# MCU_CPSW0_ECC register map
Vendor: Texas Instruments
Peripheral module from a debugger description file (folder am65x).
Registers are 32-bit, access not given, reset 0x0 unless marked. A register's access mark holds for its fields unless they carry their own. Offsets are as the file gives them; lines under a group give offsets from that group; [hi:lo] are bit positions; {n}, {i} and the like mark numbered series; 'fields as' and 'values as' point back to an identical list; <NAME> marks a mode.

## MCU_CPSW0_ECC
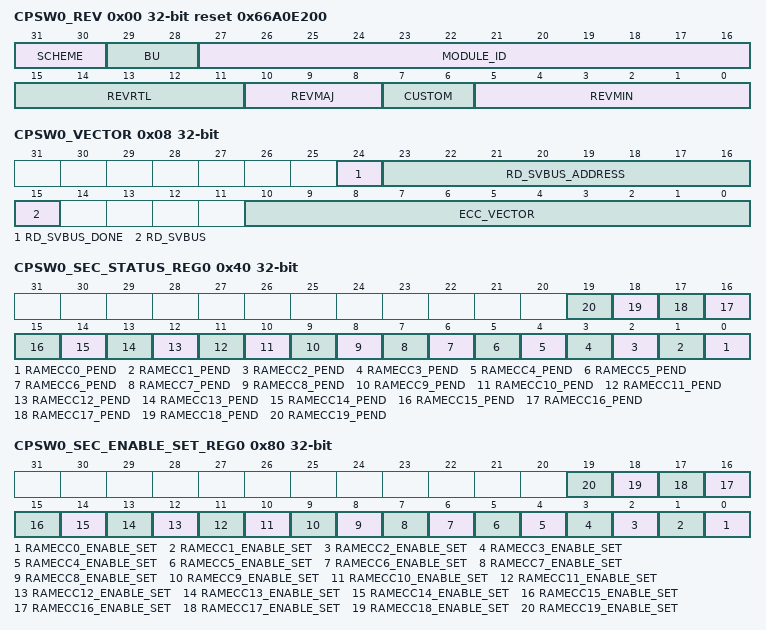
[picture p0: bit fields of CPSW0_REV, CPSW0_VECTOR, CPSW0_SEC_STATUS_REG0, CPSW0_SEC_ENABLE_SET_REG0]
0x00 CPSW0_REV ro reset 0x66A0E200 — Revision parameters
  [31:30] SCHEME
  [29:28] BU
  [27:16] MODULE_ID
  [15:11] REVRTL — RTL version
  [10:8] REVMAJ — Major version
  [7:6] CUSTOM — Custom version
  [5:0] REVMIN — Minor version
0x08 CPSW0_VECTOR — ECC Vector Register
  [24] RD_SVBUS_DONE — Status to indicate if read on serial VBUS is complete, write of any value will clear this bit. (access RW1C)
  [23:16] RD_SVBUS_ADDRESS rw — Read address
  [15] RD_SVBUS — Write 1 to trigger a read on the serial VBUS (access RW1S)
  [10:0] ECC_VECTOR rw — Value written to select the corresponding ECC RAM for
0x0C CPSW0_STAT ro reset 0x14 — Misc Status
  [10:0] NUM_RAMS — Indicates the number of RAMS serviced by the ECC aggregator
0x3C CPSW0_SEC_EOI_REG — EOI Register
  [0] EOI_WR — EOI Register (access RW1S)
0x40 CPSW0_SEC_STATUS_REG0 — Interrupt Status Register 0
  [n] RAMECC{n}_PEND (n=0..19) — Interrupt Pending Status for ramecc{n}_pend (access RW1S)
0x80 CPSW0_SEC_ENABLE_SET_REG0 — Interrupt Enable Set Register 0
  [n] RAMECC{n}_ENABLE_SET (n=0..19) — Interrupt Enable Set Register for ramecc{n}_pend (access RW1S)
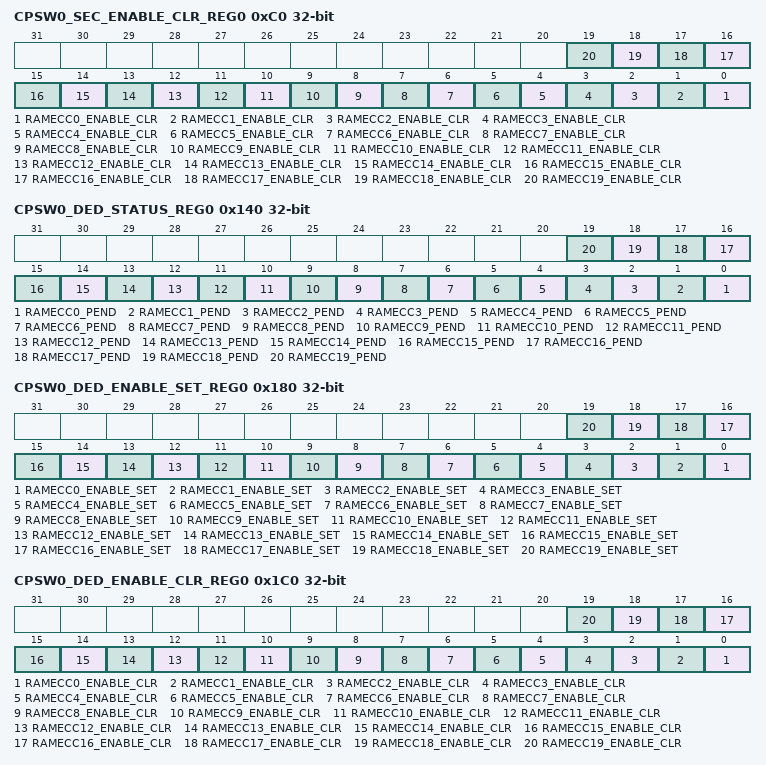
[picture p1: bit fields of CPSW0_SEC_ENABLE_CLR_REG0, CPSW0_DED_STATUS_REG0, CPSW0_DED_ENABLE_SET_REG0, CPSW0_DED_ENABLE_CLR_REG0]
0xC0 CPSW0_SEC_ENABLE_CLR_REG0 — Interrupt Enable Clear Register 0
  [n] RAMECC{n}_ENABLE_CLR (n=0..19) — Interrupt Enable Clear Register for ramecc{n}_pend (access RW1C)
0x13C CPSW0_DED_EOI_REG — EOI Register
  [0] EOI_WR — EOI Register (access RW1S)
0x140 CPSW0_DED_STATUS_REG0 — Interrupt Status Register 0
  fields as CPSW0_SEC_STATUS_REG0
0x180 CPSW0_DED_ENABLE_SET_REG0 — Interrupt Enable Set Register 0
  fields as CPSW0_SEC_ENABLE_SET_REG0
0x1C0 CPSW0_DED_ENABLE_CLR_REG0 — Interrupt Enable Clear Register 0
  fields as CPSW0_SEC_ENABLE_CLR_REG0
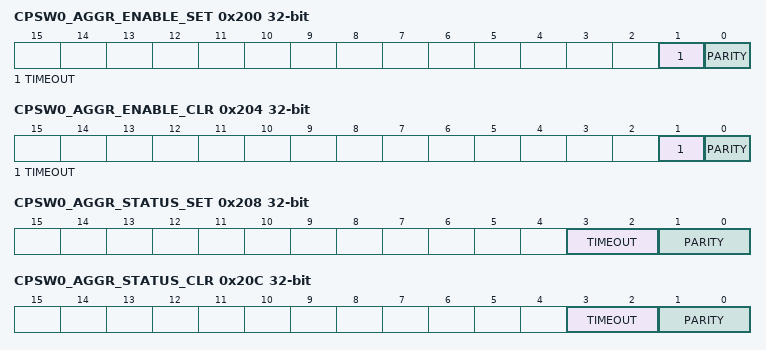
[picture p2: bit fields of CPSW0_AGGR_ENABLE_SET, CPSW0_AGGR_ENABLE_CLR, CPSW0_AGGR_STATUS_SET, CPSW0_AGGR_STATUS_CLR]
0x200 CPSW0_AGGR_ENABLE_SET — AGGR interrupt enable set Register
  [1] TIMEOUT — interrupt enable set for svbus timeout errors (access RW1S)
  [0] PARITY — interrupt enable set for parity errors (access RW1S)
0x204 CPSW0_AGGR_ENABLE_CLR — AGGR interrupt enable clear Register
  [1] TIMEOUT — interrupt enable clear for svbus timeout errors (access RW1C)
  [0] PARITY — interrupt enable clear for parity errors (access RW1C)
0x208 CPSW0_AGGR_STATUS_SET — AGGR interrupt status set Register
  [3:2] TIMEOUT — interrupt status set for svbus timeout errors (access RWincr)
  [1:0] PARITY — interrupt status set for parity errors (access RWincr)
0x20C CPSW0_AGGR_STATUS_CLR — AGGR interrupt status clear Register
  [3:2] TIMEOUT — interrupt status clear for svbus timeout errors (access RWdecr)
  [1:0] PARITY — interrupt status clear for parity errors (access RWdecr)
